# USBHOST_PRM register map
Vendor: Texas Instruments
Peripheral module from a debugger description file (folder omap34xx).
Registers are 32-bit, access per field, reset 0x1 unless marked. A register's access mark holds for its fields unless they carry their own. Offsets are as the file gives them; lines under a group give offsets from that group; [hi:lo] are bit positions; {n}, {i} and the like mark numbered series; 'fields as' and 'values as' point back to an identical list; <NAME> marks a mode.

## USBHOST_PRM
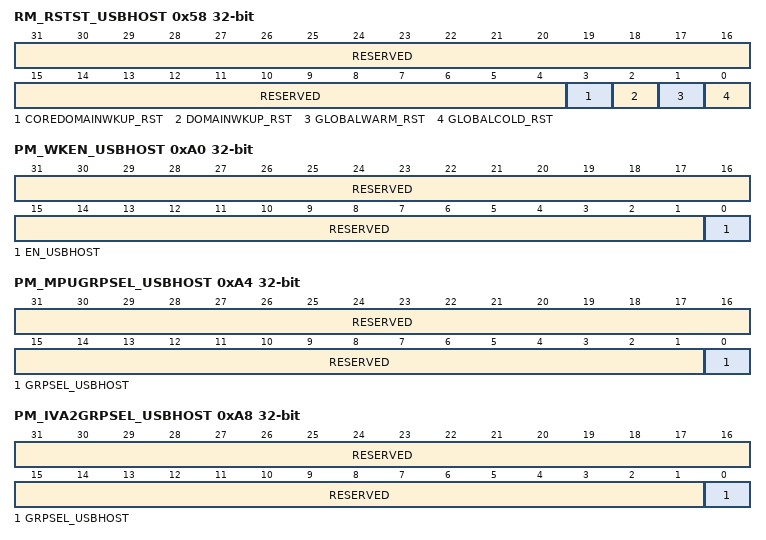
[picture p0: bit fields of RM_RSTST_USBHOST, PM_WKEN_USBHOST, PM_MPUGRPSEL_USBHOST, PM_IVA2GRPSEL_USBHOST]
0x58 RM_RSTST_USBHOST — This register logs the different reset sources of the USB HOST domain. Each bit is set upon release of the domain reset signal. Must be cleared by software.
  [31:4] RESERVED ro — Write 0s for future compatibility. Read returns 0.
  [3] COREDOMAINWKUP_RST rw — CORE domain wake-up reset
    0=COREDOMAINWKUP_RST_0_r (No power domain wake-up reset.); 0=COREDOMAINWKUP_RST_0_w (Status bit unchanged); 1=COREDOMAINWKUP_RST_1_r (USB HOST domain has been reset following a CORE power domain wake-up from OFF to ON.); 1=COREDOMAINWKUP_RST_1_w (Status bit is cleared to 0.)
  [2] DOMAINWKUP_RST rw — Power domain wake-up reset
    0=DOMAINWKUP_RST_0_r (No power domain wake-up reset.); 0=DOMAINWKUP_RST_0_w (Status bit unchanged); 1=DOMAINWKUP_RST_1_r (USB HOST domain has been reset following an USB HOST power domain wake-up.); 1=DOMAINWKUP_RST_1_w (Status bit is cleared to 0.)
  [1] GLOBALWARM_RST rw — Global warm reset
    0=GLOBALWARM_RST_0_r (No global warm reset.); 0=GLOBALWARM_RST_0_w (Status bit unchanged); 1=GLOBALWARM_RST_1_r (USB HOST domain has been reset upon a global warm reset); 1=GLOBALWARM_RST_1_w (Status bit is cleared to 0.)
  [0] GLOBALCOLD_RST rw — Global cold reset
    0=GLOBALCOLD_RST_0_r (No global cold reset.); 0=GLOBALCOLD_RST_0_w (Status bit unchanged); 1=GLOBALCOLD_RST_1_r (USB HOST domain has been reset upon a global cold reset); 1=GLOBALCOLD_RST_1_w (Status bit is cleared to 0.)
0xA0 PM_WKEN_USBHOST — This register allows enabling/disabling modules wake-up events.
  [31:1] RESERVED ro — Write 0s for future compatibility. Read returns 0.
  [0] EN_USBHOST rw — USB HOST Wake-up enable
    0=USB HOST wake-up is disabled; 1=USB HOST wake-up event is enabled
0xA4 PM_MPUGRPSEL_USBHOST — This register allows selecting the group of modules that wake-up the MPU.
  [31:1] RESERVED ro — Write 0s for future compatibility. Read returns 0.
  [0] GRPSEL_USBHOST rw — Select the USBHOST in the MPU wake-up events group
    0=USBHOST is not attached to the MPU wake-up events group; 1=USBHOST is attached to the MPU wake-up events group
0xA8 PM_IVA2GRPSEL_USBHOST — This register allows selecting the group of modules that wake-up the IVA2.
  [31:1] RESERVED ro — Write 0s for future compatibility. Read returns 0.
  [0] GRPSEL_USBHOST rw — Select the USBHOST in the IVA2 wake-up events group
    0=USBHOST is not attached to the IVA2 wake-up events group; 1=USBHOST is attached to the IVA2 wake-up events group
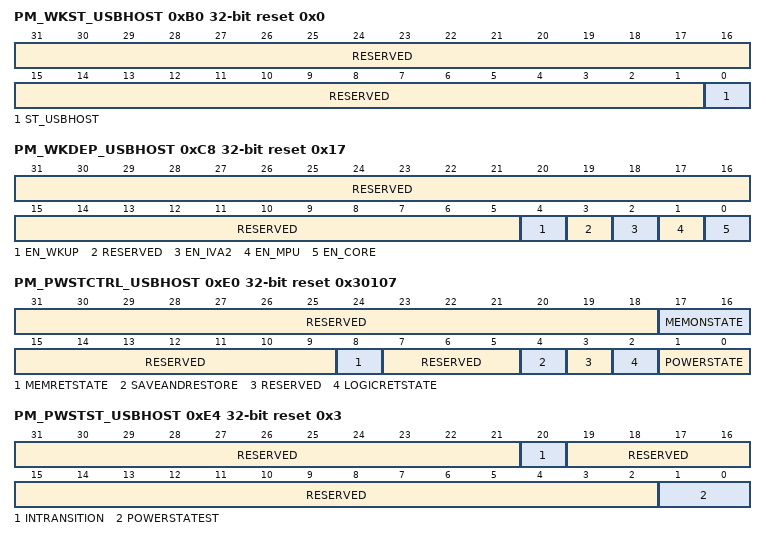
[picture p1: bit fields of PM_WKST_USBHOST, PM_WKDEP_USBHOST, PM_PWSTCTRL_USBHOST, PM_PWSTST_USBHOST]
0xB0 PM_WKST_USBHOST reset 0x0 — This register logs module wake-up events. Must be cleared by software. If it is not cleared, it prevents further domain transition.
  [31:1] RESERVED ro — Write 0s for future compatibility. Read returns 0.
  [0] ST_USBHOST rw — USB HOST Wake-up status
    0=ST_USBHOST_0_r (USB HOST wake-up did not occur or was masked.); 0=ST_USBHOST_0_w (Status bit unchanged); 1=ST_USBHOST_1_r (USB HOST wake-up occurred.); 1=ST_USBHOST_1_w (Status bit is cleared to 0.)
0xC8 PM_WKDEP_USBHOST reset 0x17 — This register allows enabling or disabling the wake-up of the USB HOST domain upon another domain wakeup.
  [31:5] RESERVED ro — Write 0s for future compatibility. Read returns 0.
  [4] EN_WKUP rw — WAKEUP domain dependency
    0=USB HOST domain is independent of WKUP domain wake-up event; 1=USB HOST domain is woken-up upon WKUP domain wake-up event
  [3] RESERVED ro — Write 0s for future compatibility. Read returns 0.
  [2] EN_IVA2 rw — IVA2 domain dependency
    0=USB HOST domain is independent of IVA2 domain wake-up event; 1=USB HOST domain is woken-up upon IVA2 domain wake-up event
  [1] EN_MPU rw — MPU domain dependency
    0=USB HOST domain is independent of MPU domain wake-up; 1=USB HOST domain is woken-up upon MPU domain wake-up
  [0] EN_CORE rw — CORE domain dependency
    0=USB HOST domain is independent of CORE domain wake-up; 1=USB HOST domain is woken-up upon CORE domain wake-up
0xE0 PM_PWSTCTRL_USBHOST reset 0x30107 — This register controls the USB HOST domain power state transition.
  [31:18] RESERVED ro — Write 0s for future compatibility. Read returns 0.
  [17:16] MEMONSTATE ro — Memory state when ON
    3=Memory is always ON when domain is ON
  [15:9] RESERVED ro — Write 0s for future compatibility. Read returns 0.
  [8] MEMRETSTATE ro — Memory state when RETENTION
    1=Memory is always retained when domain is in RETENTION state
  [7:5] RESERVED ro — Write 0s for future compatibility. Read returns 0.
  [4] SAVEANDRESTORE rw — Save And Restore mechanism for the USB HOST module
    0=Disable the save and restore mechanism for the USB HOST module; 1=Enable the save and restore mechanism for the USB HOST module
  [3] RESERVED ro — Write 0s for future compatibility. Read returns 0.
  [2] LOGICRETSTATE ro — Logic state when RETENTION
    1=Logic is always retained when domain is in RETENTION state
  [1:0] POWERSTATE rw — Power state control
    0=OFF state; 1=RETENTION state; 3=ON state
0xE4 PM_PWSTST_USBHOST ro reset 0x3 — This register provides a status on the power state transition of the USB HOST domain.
  [31:21] RESERVED — Write 0s for future compatibility. Read returns 0.
  [20] INTRANSITION — Domain transition status
    0=No transition; 1=USB HOST power domain transition is in progress
  [19:2] RESERVED — Write 0s for future compatibility. Read returns 0.
  [1:0] POWERSTATEST — Current power state status
    0=Power domain is OFF; 1=Power domain is in RETENTION; 2=Power domain is INACTIVE; 3=Power domain is ON
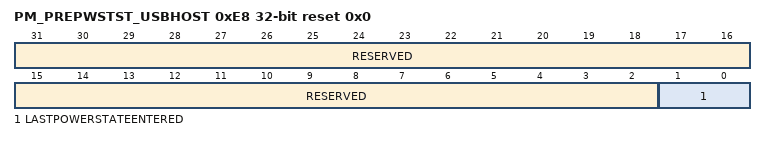
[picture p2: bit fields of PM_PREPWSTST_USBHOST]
0xE8 PM_PREPWSTST_USBHOST reset 0x0 — This register provides a status on the USBHOST domain previous power state. It indicates the state entered during the last sleep transition.
  [31:2] RESERVED ro — Write 0s for future compatibility. Read returns 0.
  [1:0] LASTPOWERSTATEENTERED rw
    0=USB HOST domain was previously OFF; 1=USB HOST domain was previously in RETENTION; 2=USB HOST domain was previously INACTIVE; 3=USB HOST domain was previously ON
